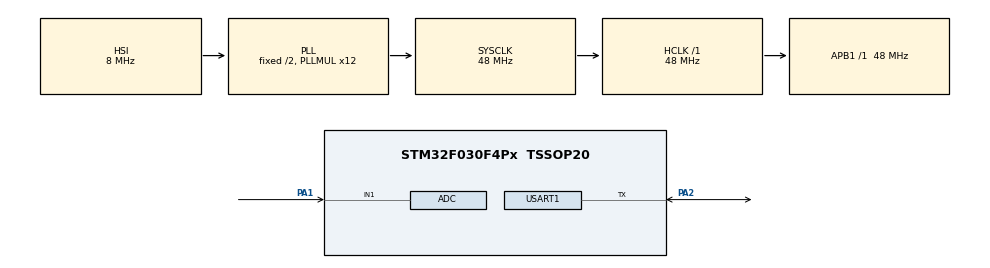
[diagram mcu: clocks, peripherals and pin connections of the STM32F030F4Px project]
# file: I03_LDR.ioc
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ADC.ClockPrescaler=ADC_CLOCK_ASYNC_DIV1
ADC.ContinuousConvMode=DISABLE
ADC.DMAContinuousRequests=DISABLE
ADC.DataAlign=ADC_DATAALIGN_RIGHT
ADC.DiscontinuousConvMode=DISABLE
ADC.EOCSelection=ADC_EOC_SINGLE_CONV
ADC.EnableAnalogWatchDog=false
ADC.ExternalTrigConv=ADC_SOFTWARE_START
ADC.ExternalTrigConvEdge=ADC_EXTERNALTRIGCONVEDGE_NONE
ADC.LowPowerAutoPowerOff=DISABLE
ADC.LowPowerAutoWait=DISABLE
ADC.Overrun=ADC_OVR_DATA_PRESERVED
ADC.Resolution=ADC_RESOLUTION_12B
ADC.SamplingTime=ADC_SAMPLETIME_239CYCLES_5
ADC.ScanConvMode=ADC_SCAN_DIRECTION_FORWARD
Mcu.Family=STM32F0
Mcu.Name=STM32F030F4Px
Mcu.Package=TSSOP20
PA1.Mode=IN1
PA1.Signal=ADC_IN1
PA13.Mode=Serial_Wire
PA13.Signal=SYS_SWDIO
PA14.Mode=Serial_Wire
PA14.Signal=SYS_SWCLK
PA2.Mode=Half_duplex(single_wire_mode)
PA2.Signal=USART1_TX
ProjectManager.HeapSize=0x200
ProjectManager.StackSize=0x400
ProjectManager.TargetToolchain=TrueSTUDIO
RCC.AHBFreq_Value=48000000
RCC.APB1Freq_Value=48000000
RCC.APB1TimFreq_Value=48000000
RCC.HCLKFreq_Value=48000000
RCC.PLLMUL=RCC_PLL_MUL12
RCC.SYSCLKFreq_VALUE=48000000
RCC.SYSCLKSource=RCC_SYSCLKSOURCE_PLLCLK
USART1.VirtualMode-Half_duplex(single_wire_mode)=VM_ASYNC
board=I03_LDR

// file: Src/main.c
/**
  ******************************************************************************
  * File Name          : main.c
  * Description        : Main program body
  ******************************************************************************
  ** This notice applies to any and all portions of this file
  * that are not between comment pairs USER CODE BEGIN and
  * USER CODE END. Other portions of this file, whether
  * inserted by the user or by software development tools
  * are owned by their respective copyright owners.
  *
  * COPYRIGHT(c) 2018 STMicroelectronics
  *
  * Redistribution and use in source and binary forms, with or without modification,
  * are permitted provided that the following conditions are met:
  *   1. Redistributions of source code must retain the above copyright notice,
  *      this list of conditions and the following disclaimer.
  *   2. Redistributions in binary form must reproduce the above copyright notice,
  *      this list of conditions and the following disclaimer in the documentation
  *      and/or other materials provided with the distribution.
  *   3. Neither the name of STMicroelectronics nor the names of its contributors
  *      may be used to endorse or promote products derived from this software
  *      without specific prior written permission.
  *
  * THIS SOFTWARE IS PROVIDED BY THE COPYRIGHT HOLDERS AND CONTRIBUTORS "AS IS"
  * AND ANY EXPRESS OR IMPLIED WARRANTIES, INCLUDING, BUT NOT LIMITED TO, THE
  * IMPLIED WARRANTIES OF MERCHANTABILITY AND FITNESS FOR A PARTICULAR PURPOSE ARE
  * DISCLAIMED. IN NO EVENT SHALL THE COPYRIGHT HOLDER OR CONTRIBUTORS BE LIABLE
  * FOR ANY DIRECT, INDIRECT, INCIDENTAL, SPECIAL, EXEMPLARY, OR CONSEQUENTIAL
  * DAMAGES (INCLUDING, BUT NOT LIMITED TO, PROCUREMENT OF SUBSTITUTE GOODS OR
  * SERVICES; LOSS OF USE, DATA, OR PROFITS; OR BUSINESS INTERRUPTION) HOWEVER
  * CAUSED AND ON ANY THEORY OF LIABILITY, WHETHER IN CONTRACT, STRICT LIABILITY,
  * OR TORT (INCLUDING NEGLIGENCE OR OTHERWISE) ARISING IN ANY WAY OUT OF THE USE
  * OF THIS SOFTWARE, EVEN IF ADVISED OF THE POSSIBILITY OF SUCH DAMAGE.
  *
  ******************************************************************************
  */
#include "main.h"
#include "stm32f0xx_hal.h"

/* USER CODE BEGIN Includes */

#include <string.h>

/* USER CODE END Includes */

ADC_HandleTypeDef hadc;

UART_HandleTypeDef huart1;

/* USER CODE BEGIN PV */
/* Private variables ---------------------------------------------------------*/

/* USER CODE END PV */

void SystemClock_Config(void);
static void MX_GPIO_Init(void);
static void MX_ADC_Init(void);
static void MX_USART1_UART_Init(void);

/* USER CODE BEGIN PFP */
/* Private function prototypes -----------------------------------------------*/

/* USER CODE END PFP */

/* USER CODE BEGIN 0 */

// message for UART
char msg[30];

// variable to hold ADC value
uint16_t adcValue;

/* USER CODE END 0 */

int main(void)
{

  /* MCU Configuration----------------------------------------------------------*/

  /* Reset of all peripherals, Initializes the Flash interface and the Systick. */
  HAL_Init();

  /* Configure the system clock */
  SystemClock_Config();

  /* Initialize all configured peripherals */
  MX_GPIO_Init();
  MX_ADC_Init();
  MX_USART1_UART_Init();

  /* USER CODE BEGIN 2 */

  HAL_ADC_Start(&hadc);

  /* USER CODE END 2 */

  /* Infinite loop */
  while (1)
  {

  /* USER CODE BEGIN 3 */

	 // perform conversion on ADC1
	 HAL_ADC_PollForConversion(&hadc, HAL_MAX_DELAY);

	 // store read value in variable
	 adcValue = HAL_ADC_GetValue(&hadc);

	 // if value is more than 80 make high
	 if (adcValue >= 80)
	 {
		 sprintf(msg, "Light\n");
	     HAL_UART_Transmit(&huart1, (uint8_t*)msg, strlen(msg), HAL_MAX_DELAY);
	 }

	 // else make low
	 else
	 {
		 sprintf(msg, "Dark\n");
		 HAL_UART_Transmit(&huart1, (uint8_t*)msg, strlen(msg), HAL_MAX_DELAY);
	 }

	 // send every second
	 HAL_Delay(1000);

  }
  /* USER CODE END 3 */

}

/** System Clock Configuration
*/
void SystemClock_Config(void)
{

  RCC_OscInitTypeDef RCC_OscInitStruct;
  RCC_ClkInitTypeDef RCC_ClkInitStruct;
  RCC_PeriphCLKInitTypeDef PeriphClkInit;

    /**Initializes the CPU, AHB and APB busses clocks
    */
  RCC_OscInitStruct.OscillatorType = RCC_OSCILLATORTYPE_HSI|RCC_OSCILLATORTYPE_HSI14;
  RCC_OscInitStruct.HSIState = RCC_HSI_ON;
  RCC_OscInitStruct.HSI14State = RCC_HSI14_ON;
  RCC_OscInitStruct.HSICalibrationValue = 16;
  RCC_OscInitStruct.HSI14CalibrationValue = 16;
  RCC_OscInitStruct.PLL.PLLState = RCC_PLL_ON;
  RCC_OscInitStruct.PLL.PLLSource = RCC_PLLSOURCE_HSI;
  RCC_OscInitStruct.PLL.PLLMUL = RCC_PLL_MUL12;
  RCC_OscInitStruct.PLL.PREDIV = RCC_PREDIV_DIV1;
  if (HAL_RCC_OscConfig(&RCC_OscInitStruct) != HAL_OK)
  {
    _Error_Handler(__FILE__, __LINE__);
  }

    /**Initializes the CPU, AHB and APB busses clocks
    */
  RCC_ClkInitStruct.ClockType = RCC_CLOCKTYPE_HCLK|RCC_CLOCKTYPE_SYSCLK
                              |RCC_CLOCKTYPE_PCLK1;
  RCC_ClkInitStruct.SYSCLKSource = RCC_SYSCLKSOURCE_PLLCLK;
  RCC_ClkInitStruct.AHBCLKDivider = RCC_SYSCLK_DIV1;
  RCC_ClkInitStruct.APB1CLKDivider = RCC_HCLK_DIV1;

  if (HAL_RCC_ClockConfig(&RCC_ClkInitStruct, FLASH_LATENCY_1) != HAL_OK)
  {
    _Error_Handler(__FILE__, __LINE__);
  }

  PeriphClkInit.PeriphClockSelection = RCC_PERIPHCLK_USART1;
  PeriphClkInit.Usart1ClockSelection = RCC_USART1CLKSOURCE_PCLK1;
  if (HAL_RCCEx_PeriphCLKConfig(&PeriphClkInit) != HAL_OK)
  {
    _Error_Handler(__FILE__, __LINE__);
  }

    /**Configure the Systick interrupt time
    */
  HAL_SYSTICK_Config(HAL_RCC_GetHCLKFreq()/1000);

    /**Configure the Systick
    */
  HAL_SYSTICK_CLKSourceConfig(SYSTICK_CLKSOURCE_HCLK);

  /* SysTick_IRQn interrupt configuration */
  HAL_NVIC_SetPriority(SysTick_IRQn, 0, 0);
}

/* ADC init function */
static void MX_ADC_Init(void)
{

  ADC_ChannelConfTypeDef sConfig;

    /**Configure the global features of the ADC (Clock, Resolution, Data Alignment and number of conversion)
    */
  hadc.Instance = ADC1;
  hadc.Init.ClockPrescaler = ADC_CLOCK_ASYNC_DIV1;
  hadc.Init.Resolution = ADC_RESOLUTION_12B;
  hadc.Init.DataAlign = ADC_DATAALIGN_RIGHT;
  hadc.Init.ScanConvMode = ADC_SCAN_DIRECTION_FORWARD;
  hadc.Init.EOCSelection = ADC_EOC_SINGLE_CONV;
  hadc.Init.LowPowerAutoWait = DISABLE;
  hadc.Init.LowPowerAutoPowerOff = DISABLE;
  hadc.Init.ContinuousConvMode = ENABLE;
  hadc.Init.DiscontinuousConvMode = DISABLE;
  hadc.Init.ExternalTrigConv = ADC_SOFTWARE_START;
  hadc.Init.ExternalTrigConvEdge = ADC_EXTERNALTRIGCONVEDGE_NONE;
  hadc.Init.DMAContinuousRequests = DISABLE;
  hadc.Init.Overrun = ADC_OVR_DATA_PRESERVED;
  if (HAL_ADC_Init(&hadc) != HAL_OK)
  {
    _Error_Handler(__FILE__, __LINE__);
  }

    /**Configure for the selected ADC regular channel to be converted.
    */
  sConfig.Channel = ADC_CHANNEL_1;
  sConfig.Rank = ADC_RANK_CHANNEL_NUMBER;
  sConfig.SamplingTime = ADC_SAMPLETIME_239CYCLES_5;
  if (HAL_ADC_ConfigChannel(&hadc, &sConfig) != HAL_OK)
  {
    _Error_Handler(__FILE__, __LINE__);
  }

}

/* USART1 init function */
static void MX_USART1_UART_Init(void)
{

  huart1.Instance = USART1;
  huart1.Init.BaudRate = 38400;
  huart1.Init.WordLength = UART_WORDLENGTH_8B;
  huart1.Init.StopBits = UART_STOPBITS_1;
  huart1.Init.Parity = UART_PARITY_NONE;
  huart1.Init.Mode = UART_MODE_TX_RX;
  huart1.Init.HwFlowCtl = UART_HWCONTROL_NONE;
  huart1.Init.OverSampling = UART_OVERSAMPLING_16;
  huart1.Init.OneBitSampling = UART_ONE_BIT_SAMPLE_DISABLE;
  huart1.AdvancedInit.AdvFeatureInit = UART_ADVFEATURE_NO_INIT;
  if (HAL_HalfDuplex_Init(&huart1) != HAL_OK)
  {
    _Error_Handler(__FILE__, __LINE__);
  }

}

/** Configure pins as
        * Analog
        * Input
        * Output
        * EVENT_OUT
        * EXTI
*/
static void MX_GPIO_Init(void)
{

  /* GPIO Ports Clock Enable */
  __HAL_RCC_GPIOA_CLK_ENABLE();

}

void _Error_Handler(char * file, int line)
{
  while(1)
  {
  }
}

/************************ (C) COPYRIGHT STMicroelectronics *****END OF FILE****/
